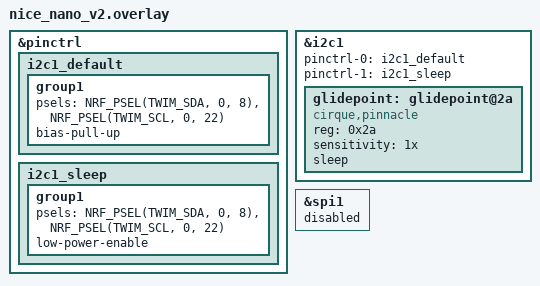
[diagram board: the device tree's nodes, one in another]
&pinctrl {
    i2c1_default: i2c1_default {
        group1 {
            psels = <NRF_PSEL(TWIM_SDA, 0, 8)>,
                <NRF_PSEL(TWIM_SCL, 0, 22)>;
            bias-pull-up;
        };
    };
    i2c1_sleep: i2c1_sleep {
        group1 {
            psels = <NRF_PSEL(TWIM_SDA, 0, 8)>,
                <NRF_PSEL(TWIM_SCL, 0, 22)>;
            low-power-enable;
        };
    };
};

glidepoint_i2c: &i2c1 {
    status = "okay";
    pinctrl-0 = < &i2c1_default >;
    pinctrl-1 = < &i2c1_sleep >;
    pinctrl-names = "default", "sleep";

    glidepoint: glidepoint@2a {
        compatible = "cirque,pinnacle";
        status = "okay";
        reg = <0x2a>;

        sensitivity = "1x";
        sleep;
    };
};

&spi1 {
    status = "disabled";
};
